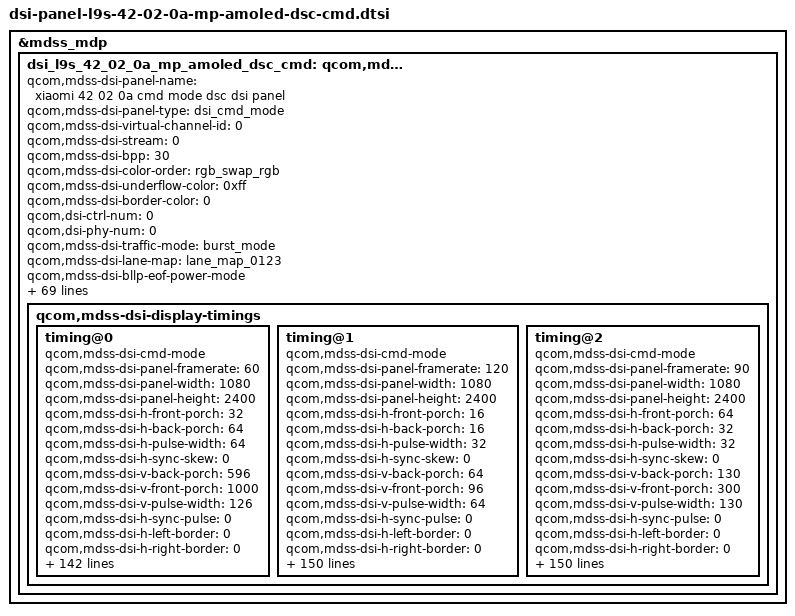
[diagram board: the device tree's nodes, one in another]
&mdss_mdp {
	dsi_l9s_42_02_0a_mp_amoled_dsc_cmd: qcom,mdss_dsi_l9s_42_02_0a_mp_amoled_dsc_cmd {
		qcom,mdss-dsi-panel-name = "xiaomi 42 02 0a cmd mode dsc dsi panel";
		qcom,mdss-dsi-panel-type = "dsi_cmd_mode";
		qcom,mdss-dsi-virtual-channel-id = <0>;
		qcom,mdss-dsi-stream = <0>;
		qcom,mdss-dsi-bpp = <30>;
		qcom,mdss-dsi-color-order = "rgb_swap_rgb";
		qcom,mdss-dsi-underflow-color = <0xff>;
		qcom,mdss-dsi-border-color = <0>;

		qcom,dsi-ctrl-num = <0>;
		qcom,dsi-phy-num = <0>;

		qcom,mdss-dsi-traffic-mode = "burst_mode";
		qcom,mdss-dsi-lane-map = "lane_map_0123";
		qcom,mdss-dsi-bllp-eof-power-mode;
		qcom,mdss-dsi-bllp-power-mode;
		qcom,mdss-dsi-lane-0-state;
		qcom,mdss-dsi-lane-1-state;
		qcom,mdss-dsi-lane-2-state;
		qcom,mdss-dsi-lane-3-state;
		qcom,mdss-dsi-dma-trigger = "trigger_sw";
		qcom,mdss-dsi-mdp-trigger = "none";
		qcom,mdss-dsi-reset-sequence =  <1 11>, <0 1>, <1 11>;
		qcom,mdss-pan-physical-width-dimension = <683>;
		qcom,mdss-pan-physical-height-dimension = <1517>;
		qcom,mdss-dsi-te-pin-select = <1>;
		qcom,mdss-dsi-wr-mem-start = <0x2c>;
		qcom,mdss-dsi-wr-mem-continue = <0x3c>;
		qcom,mdss-dsi-te-dcs-command = <1>;
		qcom,mdss-dsi-te-check-enable;
		qcom,mdss-dsi-te-using-te-pin;
		qcom,mdss-dsi-tx-eot-append;
		qcom,mdss-dsi-lp11-init;

		qcom,mdss-dsi-bl-inverted-dbv;
		qcom,bl-update-flag = "delay_until_first_frame";
		qcom,mdss-dsi-panel-mode-switch;

		qcom,mdss-dsi-panel-hdr-enabled;
		qcom,mdss-dsi-panel-hdr-color-primaries = <14500 15500 32000 17000 15500 30000 8000 3000>;
		qcom,mdss-dsi-panel-peak-brightness = <4200000>;
		qcom,mdss-dsi-panel-blackness-level = <3230>;

		qcom,mdss-dsi-display-timings {
			/* 60Hz */
			timing@0{
				qcom,mdss-dsi-cmd-mode;
				qcom,mdss-dsi-panel-framerate = <60>;
				qcom,mdss-dsi-panel-width = <1080>;
				qcom,mdss-dsi-panel-height = <2400>;
				qcom,mdss-dsi-h-front-porch = <32>;
				qcom,mdss-dsi-h-back-porch = <64>;
				qcom,mdss-dsi-h-pulse-width = <64>;
				qcom,mdss-dsi-h-sync-skew = <0>;
				qcom,mdss-dsi-v-back-porch = <596>;
				qcom,mdss-dsi-v-front-porch = <1000>;
				qcom,mdss-dsi-v-pulse-width = <126>;
				qcom,mdss-dsi-h-sync-pulse = <0>;
				qcom,mdss-dsi-h-left-border = <0>;
				qcom,mdss-dsi-h-right-border = <0>;
				qcom,mdss-dsi-v-top-border = <0>;
				qcom,mdss-dsi-v-bottom-border = <0>;
				qcom,mdss-dsi-panel-clockrate = <831000000>;
				qcom,mdss-dsi-panel-jitter = <0x5 0x1>;
				qcom,mdss-mdp-transfer-time-us = <14000>;
				qcom,mdss-dsi-on-command = [
					/* Increase VFP */
					39 00 00 00 00 00 06 F0 55 AA 52 08 00
					39 00 00 40 00 00 02 6F 08
					39 00 00 40 00 00 09 BA 01 B1 00 0A 00 16 00 00
					/* Flash load */
					39 00 00 40 00 00 06 F0 55 AA 52 08 04
					39 00 00 40 00 00 02 B1 02
					/* VBP & VFP */
					39 00 00 40 00 00 05 3B 00 14 00 0C
					/* Vesa Decode enable */
					39 00 00 40 00 00 02 90 01
					/* DSC Setting */
					39 00 00 40 00 00 13 91 AB 28 00 0C C2 00 03 1C 01 7E 00 0F 08 BB 04 3D 10 F0
					39 00 00 40 00 00 02 03 01
					39 00 00 40 00 00 02 2C 00
					/* Round Off */
					39 00 00 40 00 00 06 F0 55 AA 52 08 07
					39 00 00 40 00 00 02 C0 05
					39 00 00 40 00 00 02 C1 00
					39 00 00 40 00 00 02 C2 00
					39 00 00 40 00 00 02 C3 00
					39 00 00 40 00 00 02 C4 00
					39 00 00 40 00 00 02 C5 00
					39 00 00 40 00 00 02 C6 00
					39 00 00 40 00 00 02 C7 00
					39 00 00 40 00 00 02 C8 00
					39 00 00 40 00 00 02 CD 00
					39 00 00 40 00 00 02 CE 00
					39 00 00 40 00 00 02 CF 00
					39 00 00 40 00 00 02 D0 00
					/* Dimming OFF Setting */
					39 00 00 40 00 00 02 53 20
					/* page 0 */
					39 00 00 40 00 00 06 F0 55 AA 52 08 00
					/* Dimming 8 frame */
					39 00 00 40 00 00 02 6F 02
					39 00 00 40 00 00 03 B2 08 08
					/* TE ON Setting */
					39 00 00 40 00 00 02 35 00
					/* MIPI Speed = 831Mbps @osc 128Mhz */
					39 00 00 40 00 00 06 F0 55 AA 52 08 01
					39 00 00 40 00 00 08 C3 94 01 8C D0 22 02 00
					/* CASET/RASET Setting */
					39 00 00 40 00 00 05 2A 00 00 04 37 /* CASET 1080 */
					39 00 00 40 00 00 05 2B 00 00 09 5F /* PASET 2400 */
					/* Frame Rate 60Hz */
					39 00 00 40 00 00 02 2F 01
					/* GIR OFF */
					39 00 00 40 00 00 02 26 01
					39 00 00 40 00 00 06 F0 55 AA 52 08 00
					39 00 00 40 00 00 02 6F 05
					39 00 00 00 00 00 02 BE 88
					/* Aod no black */
					39 00 00 40 00 00 05 FF AA 55 A5 80
					39 00 00 40 00 00 02 6F 61
					39 00 00 40 00 00 02 F3 80
					39 00 00 40 00 00 06 F0 55 AA 52 08 01
					39 00 00 40 00 00 02 6F 01
					39 00 00 40 00 00 04 D2 00 00 11
					39 00 00 40 00 00 02 6F 06
					39 00 00 40 00 00 02 D2 05
					39 00 00 40 00 00 02 6F 0F
					39 00 00 40 00 00 02 D2 00
					39 00 00 40 00 00 02 6F 09
					39 00 00 00 00 00 03 D2 00 00
					/* Disable aod reload */
					39 00 00 40 00 00 06 F0 55 AA 52 08 00
					39 00 00 40 00 00 02 6F 01
					39 00 00 40 00 00 02 C0 B3
					39 00 00 40 00 00 05 FF AA 55 A5 80
					39 00 00 40 00 00 02 6F 2E
					39 00 00 40 00 00 02 FB D1
					39 00 00 40 00 00 06 F0 55 AA 52 08 04
					39 00 00 40 00 00 02 6F 0D
					39 00 00 00 00 00 02 CA 05
					/* Lhbm spot 12mm */
					39 00 00 40 00 00 06 F0 55 AA 52 08 07
					39 00 00 40 00 00 02 C0 05
					39 00 00 40 00 00 02 6F 00
					39 00 00 40 00 00 16 C9 21 00 21 C9 21 10 00 00 3F E7 B7 88 3F E7 FA 60 80 04 5D 05 90
					39 00 00 40 00 00 02 6F 15
					39 00 00 40 00 00 10 C9 81 C0 16 82 1C 73 33 A0 21 6C 0F A3 A4 00 00
					39 00 00 40 00 00 02 6F 24
					39 00 00 40 00 00 08 C9 00 00 00 00 00 00 00
					39 00 00 40 00 00 02 6F 00
					39 00 00 40 00 00 16 CA 27 00 21 C9 21 10 00 00 00 00 00 00 3F E7 FA 60 80 00 00 00 00
					39 00 00 40 00 00 02 6F 15
					39 00 00 40 00 00 10 CA 82 1D 16 82 79 73 33 A0 00 00 03 5D A4 00 00
					39 00 00 40 00 00 02 6F 24
					39 00 00 40 00 00 08 CA 00 00 00 00 00 00 00
					39 00 00 40 00 00 02 6F 00
					39 00 00 40 00 00 16 CB 2D 00 21 10 21 10 00 00 3F E8 3C 80 80 00 00 00 00 00 00 00 00
					39 00 00 40 00 00 02 6F 15
					39 00 00 40 00 00 10 CB 81 C0 74 82 1C D0 33 10 00 00 0C A4 5C 00 00
					39 00 00 40 00 00 02 6F 24
					39 00 00 40 00 00 08 CB 00 00 00 00 00 00 00
					39 00 00 40 00 00 02 6F 00
					39 00 00 40 00 00 16 CC 2B 00 21 10 21 10 00 00 00 00 00 00 80 00 00 00 7F FB BA DF 00
					39 00 00 40 00 00 02 6F 15
					39 00 00 40 00 00 10 CC 82 1D 74 82 79 D0 33 1F DE F0 00 5C 5C 00 00
					39 00 00 40 00 00 02 6F 24
					39 00 00 00 00 00 08 CC 00 00 00 00 00 00 00
					/* Sleep Out */
					39 00 00 00 50 00 02 11 00
					/* Display On */
					39 00 00 00 00 00 02 29 00];
				qcom,mdss-dsi-off-command = [
					39 00 00 00 0A 00 02 28 00
					39 00 00 00 78 00 02 10 00];
				qcom,mdss-dsi-on-command-state = "dsi_lp_mode";
				qcom,mdss-dsi-off-command-state = "dsi_lp_mode";

				qcom,mdss-dsi-timing-switch-command = [
					/* 60 Hz */
					39 00 00 00 00 00 06 F0 55 AA 52 08 02
					39 00 00 40 00 00 02 CC 00
					39 00 00 40 00 00 02 2F 01
					39 00 00 00 00 00 02 26 01
				];
				qcom,mdss-dsi-timing-switch-command-state = "dsi_hs_mode";
				qcom,mdss-dsi-timing-switch-command-update = <0x26 3 1>;

				qcom,mdss-dsi-nolp-command = [
					39 00 00 00 00 00 06 F0 55 AA 52 08 00
					39 00 00 40 00 00 02 B2 18
					39 00 00 00 32 00 02 38 00];
				qcom,mdss-dsi-nolp-command-state = "dsi_hs_mode";

				qcom,compression-mode = "dsc";
				qcom,mdss-dsc-version = <0x11>;
				qcom,mdss-dsc-scr-version = <0x0>;
				qcom,mdss-dsc-slice-height = <12>;
				qcom,mdss-dsc-slice-width = <1080>;
				qcom,mdss-dsc-slice-per-pkt = <1>;
				qcom,mdss-dsc-bit-per-component = <10>;
				qcom,mdss-dsc-bit-per-pixel = <8>;
				qcom,mdss-dsc-block-prediction-enable;
			};
			/* 120hz */
			timing@1{
				qcom,mdss-dsi-cmd-mode;
				qcom,mdss-dsi-panel-framerate = <120>;
				qcom,mdss-dsi-panel-width = <1080>;
				qcom,mdss-dsi-panel-height = <2400>;
				qcom,mdss-dsi-h-front-porch = <16>;
				qcom,mdss-dsi-h-back-porch = <16>;
				qcom,mdss-dsi-h-pulse-width = <32>;
				qcom,mdss-dsi-h-sync-skew = <0>;
				qcom,mdss-dsi-v-back-porch = <64>;
				qcom,mdss-dsi-v-front-porch = <96>;
				qcom,mdss-dsi-v-pulse-width = <64>;
				qcom,mdss-dsi-h-sync-pulse = <0>;
				qcom,mdss-dsi-h-left-border = <0>;
				qcom,mdss-dsi-h-right-border = <0>;
				qcom,mdss-dsi-v-top-border = <0>;
				qcom,mdss-dsi-v-bottom-border = <0>;
				qcom,mdss-dsi-panel-clockrate = <831000000>;
				qcom,mdss-dsi-panel-jitter = <0x5 0x1>;
				qcom,mdss-mdp-transfer-time-us = <8000>;
				qcom,mdss-dsi-on-command = [
					/* Increase VFP */
					39 00 00 00 00 00 06 F0 55 AA 52 08 00
					39 00 00 40 00 00 02 6F 08
					39 00 00 40 00 00 09 BA 01 B1 00 0A 00 16 00 00
					/* Flash load */
					39 00 00 40 00 00 06 F0 55 AA 52 08 04
					39 00 00 40 00 00 02 B1 02
					/* VBP & VFP */
					39 00 00 40 00 00 05 3B 00 14 00 0C
					/* Vesa Decode enable */
					39 00 00 40 00 00 02 90 01
					/* DSC Setting */
					39 00 00 40 00 00 13 91 AB 28 00 0C C2 00 03 1C 01 7E 00 0F 08 BB 04 3D 10 F0
					39 00 00 40 00 00 02 03 01
					39 00 00 40 00 00 02 2C 00
					/* Round Off */
					39 00 00 40 00 00 06 F0 55 AA 52 08 07
					39 00 00 40 00 00 02 C0 05
					39 00 00 40 00 00 02 C1 00
					39 00 00 40 00 00 02 C2 00
					39 00 00 40 00 00 02 C3 00
					39 00 00 40 00 00 02 C4 00
					39 00 00 40 00 00 02 C5 00
					39 00 00 40 00 00 02 C6 00
					39 00 00 40 00 00 02 C7 00
					39 00 00 40 00 00 02 C8 00
					39 00 00 40 00 00 02 CD 00
					39 00 00 40 00 00 02 CE 00
					39 00 00 40 00 00 02 CF 00
					39 00 00 40 00 00 02 D0 00
					/* Dimming OFF Setting */
					39 00 00 40 00 00 02 53 20
					/* page 0 */
					39 00 00 40 00 00 06 F0 55 AA 52 08 00
					/* Dimming 8 frame */
					39 00 00 40 00 00 02 6F 02
					39 00 00 40 00 00 03 B2 08 08
					/* TE ON Setting */
					39 00 00 40 00 00 02 35 00
					/* MIPI Speed = 831Mbps @osc 128Mhz */
					39 00 00 40 00 00 06 F0 55 AA 52 08 01
					39 00 00 40 00 00 08 C3 94 01 8C D0 22 02 00
					/* CASET/RASET Setting */
					39 00 00 40 00 00 05 2A 00 00 04 37 /* CASET 1080 */
					39 00 00 40 00 00 05 2B 00 00 09 5F /* PASET 2400 */
					/* Frame Rate 120Hz */
					39 00 00 40 00 00 02 2F 02
					/* GIR OFF */
					39 00 00 40 00 00 06 F0 55 AA 52 08 00
					39 00 00 40 00 00 02 6F 09
					39 00 00 40 00 00 02 C0 20
					39 00 00 40 00 00 06 F0 55 AA 52 08 02
					39 00 00 40 00 00 02 CC 30
					39 00 00 40 14 00 02 CE 01
					39 00 00 40 00 00 02 CC 00
					39 00 00 40 00 00 06 F0 55 AA 52 08 00
					39 00 00 40 00 00 02 6F 05
					39 00 00 00 00 00 02 BE 88
					/* Aod no black */
					39 00 00 40 00 00 05 FF AA 55 A5 80
					39 00 00 40 00 00 02 6F 61
					39 00 00 40 00 00 02 F3 80
					39 00 00 40 00 00 06 F0 55 AA 52 08 01
					39 00 00 40 00 00 02 6F 01
					39 00 00 40 00 00 04 D2 00 00 11
					39 00 00 40 00 00 02 6F 06
					39 00 00 40 00 00 02 D2 05
					39 00 00 40 00 00 02 6F 0F
					39 00 00 40 00 00 02 D2 00
					39 00 00 40 00 00 02 6F 09
					39 00 00 00 00 00 03 D2 00 00
					/* Disable aod reload */
					39 00 00 40 00 00 06 F0 55 AA 52 08 00
					39 00 00 40 00 00 02 6F 01
					39 00 00 40 00 00 02 C0 B3
					39 00 00 40 00 00 05 FF AA 55 A5 80
					39 00 00 40 00 00 02 6F 2E
					39 00 00 40 00 00 02 FB D1
					39 00 00 40 00 00 06 F0 55 AA 52 08 04
					39 00 00 40 00 00 02 6F 0D
					39 00 00 00 00 00 02 CA 05
					/* Lhbm spot 12mm */
					39 00 00 40 00 00 06 F0 55 AA 52 08 07
					39 00 00 40 00 00 02 C0 05
					39 00 00 40 00 00 02 6F 00
					39 00 00 40 00 00 16 C9 21 00 21 C9 21 10 00 00 3F E7 B7 88 3F E7 FA 60 80 04 5D 05 90
					39 00 00 40 00 00 02 6F 15
					39 00 00 40 00 00 10 C9 81 C0 16 82 1C 73 33 A0 21 6C 0F A3 A4 00 00
					39 00 00 40 00 00 02 6F 24
					39 00 00 40 00 00 08 C9 00 00 00 00 00 00 00
					39 00 00 40 00 00 02 6F 00
					39 00 00 40 00 00 16 CA 27 00 21 C9 21 10 00 00 00 00 00 00 3F E7 FA 60 80 00 00 00 00
					39 00 00 40 00 00 02 6F 15
					39 00 00 40 00 00 10 CA 82 1D 16 82 79 73 33 A0 00 00 03 5D A4 00 00
					39 00 00 40 00 00 02 6F 24
					39 00 00 40 00 00 08 CA 00 00 00 00 00 00 00
					39 00 00 40 00 00 02 6F 00
					39 00 00 40 00 00 16 CB 2D 00 21 10 21 10 00 00 3F E8 3C 80 80 00 00 00 00 00 00 00 00
					39 00 00 40 00 00 02 6F 15
					39 00 00 40 00 00 10 CB 81 C0 74 82 1C D0 33 10 00 00 0C A4 5C 00 00
					39 00 00 40 00 00 02 6F 24
					39 00 00 40 00 00 08 CB 00 00 00 00 00 00 00
					39 00 00 40 00 00 02 6F 00
					39 00 00 40 00 00 16 CC 2B 00 21 10 21 10 00 00 00 00 00 00 80 00 00 00 7F FB BA DF 00
					39 00 00 40 00 00 02 6F 15
					39 00 00 40 00 00 10 CC 82 1D 74 82 79 D0 33 1F DE F0 00 5C 5C 00 00
					39 00 00 40 00 00 02 6F 24
					39 00 00 00 00 00 08 CC 00 00 00 00 00 00 00
					/* Sleep Out */
					39 00 00 00 50 00 02 11 00
					/* Display On */
					39 00 00 00 00 00 02 29 00];
				qcom,mdss-dsi-off-command = [
					39 00 00 00 14 00 02 28 00
					39 00 00 00 78 00 02 10 00];
				qcom,mdss-dsi-on-command-state = "dsi_lp_mode";
				qcom,mdss-dsi-off-command-state = "dsi_lp_mode";

				qcom,mdss-dsi-timing-switch-command = [
					/* 120 Hz   cmd_1*/
					39 00 00 00 00 00 02 2F 02
					39 00 00 40 00 00 06 F0 55 AA 52 08 00
					39 00 00 40 00 00 02 6F 09
					39 00 00 40 00 00 02 C0 20
					39 00 00 40 00 00 06 F0 55 AA 52 08 02
					39 00 00 40 00 00 02 CC 30
					39 00 00 00 14 00 02 CE 01
					/*120 Hz  cmd_2*/
					39 00 00 00 00 00 06 F0 55 AA 52 08 02
					39 00 00 00 00 00 02 CC 00
				];
				qcom,mdss-dsi-timing-switch-command-update = <0xC0 3 1>;
				qcom,mdss-dsi-timing-switch-command-state = "dsi_hs_mode";

				qcom,mdss-dsi-nolp-command = [
					39 00 00 00 00 00 06 F0 55 AA 52 08 00
					39 00 00 40 00 00 02 B2 18
					39 00 00 00 00 00 02 38 00
					39 00 00 00 00 00 02 2F 02];
				qcom,mdss-dsi-nolp-command-state = "dsi_hs_mode";

				qcom,compression-mode = "dsc";
				qcom,mdss-dsc-version = <0x11>;
				qcom,mdss-dsc-scr-version = <0x0>;
				qcom,mdss-dsc-slice-height = <12>;
				qcom,mdss-dsc-slice-width = <1080>;
				qcom,mdss-dsc-slice-per-pkt = <1>;
				qcom,mdss-dsc-bit-per-component = <10>;
				qcom,mdss-dsc-bit-per-pixel = <8>;
				qcom,mdss-dsc-block-prediction-enable;
			};
			/* 90hz */
			timing@2{
				qcom,mdss-dsi-cmd-mode;
				qcom,mdss-dsi-panel-framerate = <90>;
				qcom,mdss-dsi-panel-width = <1080>;
				qcom,mdss-dsi-panel-height = <2400>;
				qcom,mdss-dsi-h-front-porch = <64>;
				qcom,mdss-dsi-h-back-porch = <32>;
				qcom,mdss-dsi-h-pulse-width = <32>;
				qcom,mdss-dsi-h-sync-skew = <0>;
				qcom,mdss-dsi-v-back-porch = <130>;
				qcom,mdss-dsi-v-front-porch = <300>;
				qcom,mdss-dsi-v-pulse-width = <130>;
				qcom,mdss-dsi-h-sync-pulse = <0>;
				qcom,mdss-dsi-h-left-border = <0>;
				qcom,mdss-dsi-h-right-border = <0>;
				qcom,mdss-dsi-v-top-border = <0>;
				qcom,mdss-dsi-v-bottom-border = <0>;
				qcom,mdss-dsi-panel-clockrate = <831000000>;
				qcom,mdss-dsi-panel-jitter = <0x5 0x1>;
				qcom,mdss-mdp-transfer-time-us = <10000>;
				qcom,mdss-dsi-on-command = [
					/* Increase VFP */
					39 00 00 40 00 00 06 F0 55 AA 52 08 00
					39 00 00 40 00 00 02 6F 08
					39 00 00 40 00 00 09 BA 01 B1 00 0A 00 16 00 00
					/* Flash load */
					39 00 00 40 00 00 06 F0 55 AA 52 08 04
					39 00 00 40 00 00 02 B1 02
					/* VBP & VFP */
					39 00 00 40 00 00 05 3B 00 14 00 0C
					/* Vesa Decode enable */
					39 00 00 40 00 00 02 90 01
					/* DSC Setting */
					39 00 00 40 00 00 13 91 AB 28 00 0C C2 00 03 1C 01 7E 00 0F 08 BB 04 3D 10 F0
					39 00 00 40 00 00 02 03 01
					39 00 00 40 00 00 02 2C 00
					/* Round Off */
					39 00 00 40 00 00 06 F0 55 AA 52 08 07
					39 00 00 40 00 00 02 C0 05
					39 00 00 40 00 00 02 C1 00
					39 00 00 40 00 00 02 C2 00
					39 00 00 40 00 00 02 C3 00
					39 00 00 40 00 00 02 C4 00
					39 00 00 40 00 00 02 C5 00
					39 00 00 40 00 00 02 C6 00
					39 00 00 40 00 00 02 C7 00
					39 00 00 40 00 00 02 C8 00
					39 00 00 40 00 00 02 CD 00
					39 00 00 40 00 00 02 CE 00
					39 00 00 40 00 00 02 CF 00
					39 00 00 40 00 00 02 D0 00
					/* Dimming OFF Setting */
					39 00 00 40 00 00 02 53 20
					/* page 0 */
					39 00 00 40 00 00 06 F0 55 AA 52 08 00
					/* Dimming 8 frame */
					39 00 00 40 00 00 02 6F 02
					39 00 00 40 00 00 03 B2 08 08
					/* TE ON Setting */
					39 00 00 40 00 00 02 35 00
					/* MIPI Speed = 831Mbps @osc 128Mhz */
					39 00 00 40 00 00 06 F0 55 AA 52 08 01
					39 00 00 40 00 00 08 C3 94 01 8C D0 22 02 00
					/* CASET/RASET Setting */
					39 00 00 40 00 00 05 2A 00 00 04 37 /* CASET 1080 */
					39 00 00 40 00 00 05 2B 00 00 09 5F /* PASET 2400 */
					/* Frame Rate 90Hz */
					39 00 00 40 00 00 02 2F 03
					/* GIR OFF */
					39 00 00 40 00 00 06 F0 55 AA 52 08 00
					39 00 00 40 00 00 02 6F 0A
					39 00 00 40 00 00 02 C0 20
					39 00 00 40 00 00 06 F0 55 AA 52 08 02
					39 00 00 40 00 00 02 CC 30
					39 00 00 40 14 00 02 CE 01
					39 00 00 40 00 00 02 CC 00
					39 00 00 40 00 00 06 F0 55 AA 52 08 00
					39 00 00 40 00 00 02 6F 05
					39 00 00 00 00 00 02 BE 88
					/* Aod no black */
					39 00 00 40 00 00 05 FF AA 55 A5 80
					39 00 00 40 00 00 02 6F 61
					39 00 00 40 00 00 02 F3 80
					39 00 00 40 00 00 06 F0 55 AA 52 08 01
					39 00 00 40 00 00 02 6F 01
					39 00 00 40 00 00 04 D2 00 00 11
					39 00 00 40 00 00 02 6F 06
					39 00 00 40 00 00 02 D2 05
					39 00 00 40 00 00 02 6F 0F
					39 00 00 40 00 00 02 D2 00
					39 00 00 40 00 00 02 6F 09
					39 00 00 00 00 00 03 D2 00 00
					/* Disable aod reload */
					39 00 00 40 00 00 06 F0 55 AA 52 08 00
					39 00 00 40 00 00 02 6F 01
					39 00 00 40 00 00 02 C0 B3
					39 00 00 40 00 00 05 FF AA 55 A5 80
					39 00 00 40 00 00 02 6F 2E
					39 00 00 40 00 00 02 FB D1
					39 00 00 40 00 00 06 F0 55 AA 52 08 04
					39 00 00 40 00 00 02 6F 0D
					39 00 00 00 00 00 02 CA 05
					/* Lhbm spot 12mm */
					39 00 00 40 00 00 06 F0 55 AA 52 08 07
					39 00 00 40 00 00 02 C0 05
					39 00 00 40 00 00 02 6F 00
					39 00 00 40 00 00 16 C9 21 00 21 C9 21 10 00 00 3F E7 B7 88 3F E7 FA 60 80 04 5D 05 90
					39 00 00 40 00 00 02 6F 15
					39 00 00 40 00 00 10 C9 81 C0 16 82 1C 73 33 A0 21 6C 0F A3 A4 00 00
					39 00 00 40 00 00 02 6F 24
					39 00 00 40 00 00 08 C9 00 00 00 00 00 00 00
					39 00 00 40 00 00 02 6F 00
					39 00 00 40 00 00 16 CA 27 00 21 C9 21 10 00 00 00 00 00 00 3F E7 FA 60 80 00 00 00 00
					39 00 00 40 00 00 02 6F 15
					39 00 00 40 00 00 10 CA 82 1D 16 82 79 73 33 A0 00 00 03 5D A4 00 00
					39 00 00 40 00 00 02 6F 24
					39 00 00 40 00 00 08 CA 00 00 00 00 00 00 00
					39 00 00 40 00 00 02 6F 00
					39 00 00 40 00 00 16 CB 2D 00 21 10 21 10 00 00 3F E8 3C 80 80 00 00 00 00 00 00 00 00
					39 00 00 40 00 00 02 6F 15
					39 00 00 40 00 00 10 CB 81 C0 74 82 1C D0 33 10 00 00 0C A4 5C 00 00
					39 00 00 40 00 00 02 6F 24
					39 00 00 40 00 00 08 CB 00 00 00 00 00 00 00
					39 00 00 40 00 00 02 6F 00
					39 00 00 40 00 00 16 CC 2B 00 21 10 21 10 00 00 00 00 00 00 80 00 00 00 7F FB BA DF 00
					39 00 00 40 00 00 02 6F 15
					39 00 00 40 00 00 10 CC 82 1D 74 82 79 D0 33 1F DE F0 00 5C 5C 00 00
					39 00 00 40 00 00 02 6F 24
					39 00 00 00 00 00 08 CC 00 00 00 00 00 00 00
					/* Sleep Out */
					39 00 00 00 50 00 02 11 00
					/* Display On */
					39 00 00 00 00 00 02 29 00];
				qcom,mdss-dsi-off-command = [
					39 00 00 00 14 00 02 28 00
					39 00 00 00 78 00 02 10 00];
				qcom,mdss-dsi-on-command-state = "dsi_lp_mode";
				qcom,mdss-dsi-off-command-state = "dsi_lp_mode";

				qcom,mdss-dsi-timing-switch-command = [
					/* 90 Hz  cmd_1*/
					39 00 00 00 00 00 02 2F 03
					39 00 00 40 00 00 06 F0 55 AA 52 08 00
					39 00 00 40 00 00 02 6F 0A
					39 00 00 40 00 00 02 C0 20
					39 00 00 40 00 00 06 F0 55 AA 52 08 02
					39 00 00 40 00 00 02 CC 30
					39 00 00 00 14 00 02 CE 01
					/* 90 Hz  */
					39 00 00 00 00 00 06 F0 55 AA 52 08 02
					39 00 00 00 00 00 02 CC 00
				];
				qcom,mdss-dsi-timing-switch-command-update = <0xC0 3 1>;
				qcom,mdss-dsi-timing-switch-command-state = "dsi_hs_mode";

				qcom,mdss-dsi-nolp-command = [
					39 00 00 00 00 00 06 F0 55 AA 52 08 00
					39 00 00 40 00 00 02 B2 18
					39 00 00 00 00 00 02 38 00
					39 00 00 00 00 00 02 2F 03];
				qcom,mdss-dsi-nolp-command-state = "dsi_hs_mode";

				qcom,compression-mode = "dsc";
				qcom,mdss-dsc-version = <0x11>;
				qcom,mdss-dsc-scr-version = <0x0>;
				qcom,mdss-dsc-slice-height = <12>;
				qcom,mdss-dsc-slice-width = <1080>;
				qcom,mdss-dsc-slice-per-pkt = <1>;
				qcom,mdss-dsc-bit-per-component = <10>;
				qcom,mdss-dsc-bit-per-pixel = <8>;
				qcom,mdss-dsc-block-prediction-enable;
			};
		};
	};
};

&dsi_l9s_42_02_0a_mp_amoled_dsc_cmd {
	mi,panel-id = <0x004C3953 0x00420200>;
	mi,hbm-51-ctl-flag;
	mi,bl-51ctl-32bit-flag;
	mi,aod-bl-51ctl-flag;
	mi,aod-brightness = <0x155 0x0FFE>;
	mi,hbm-off-51-index = <0>;
	mi,hbm-fod-off-51-index = <0>;
	mi,hbm-bl-min-level = <1>;
	mi,hbm-bl-max-level = <2047>;
	mi,max-brightness-clone = <4095>;
	mi,mdss-dsi-fac-bl-max-level = <2047>;
	mi,mdss-fac-brightness-max-level = <2047>;
	mi,thermal-dimming-flag;
	mi,mdss-dsi-panel-dc-type = <0>;

	mi,local-hbm-enabled;
	mi,doze-hbm-dbv-level = <245>;
	mi,doze-lbm-dbv-level = <20>;
	mi,fod-low-brightness-clone-threshold = <38>;
	mi,fod-low-brightness-lux-threshold = <1>;
	mi,local-hbm-white-1000nit-update-flag;
	mi,local-hbm-white-110nit-update-flag;
	mi,local-hbm-green-500nit-update-flag;
	mi,local-hbm-alpha-ctrl-aa-area;
	mi,need-fod-animal-in-normal-enabled;

	mi,flat-update-flag;
	mi,flat-need-sync-te;

	/* IRQF_ONESHOT | IRQF_TRIGGER_LOW */
	mi,esd-err-irq-gpio = <&tlmm 11 0x2008>;

	mi,panel-aod-to-off-command-need-enabled;

	mi,panel-on-dimming-delay = <120>;

	qcom,esd-check-enabled;
	qcom,esd-aod-check-enabled;
	qcom,mdss-dsi-panel-status-check-mode = "reg_read";
	qcom,mdss-dsi-panel-status-offset-command = [
		39 01 00 00 00 00 05 FF AA 55 A5 81
		15 01 00 00 00 00 02 6F 0F];
	qcom,mdss-dsi-panel-status-command = [06 01 00 00 00 00 01 FA];
	qcom,mdss-dsi-panel-status-command-state = "dsi_lp_mode";
	qcom,mdss-dsi-panel-status-offset-command-state = "dsi_lp_mode";
	qcom,mdss-dsi-panel-status-value = <0x00>;
	qcom,mdss-dsi-panel-status-read-length = <1>;

	qcom,mdss-dsi-display-timings {
		/* 60Hz */
		timing@0{
			mi,mdss-dsc-panel-id = <0x004C3953 0x00420200>;
			/*<flat on gamma, flat off gamma>*/
			mi,mdss-flat-status-control-gamma-cfg = <0x04 0x01>;
			mi,mdss-dsi-dimmingon-command = [39 00 00 00 00 00 02 53 28];
			mi,mdss-dsi-dimmingon-command-state = "dsi_hs_mode";
			mi,mdss-dsi-dimmingoff-command = [39 00 00 00 00 00 02 53 20];
			mi,mdss-dsi-dimmingoff-command-state = "dsi_hs_mode";

			mi,mdss-dsi-hbm-on-command = [39 00 00 00 00 00 05 51 0F FF 00 00];
			mi,mdss-dsi-hbm-on-command-state = "dsi_lp_mode";
			mi,mdss-dsi-hbm-off-command = [39 00 00 00 00 00 05 51 07 FF 00 00];
			mi,mdss-dsi-hbm-off-command-state = "dsi_lp_mode";
			mi,mdss-dsi-switch-page-command = [
			/* switch page, last byte is page config */
				39 00 00 00 00 00 06 F0 55 AA 52 08 00
			];
			/* <mipi_address  update_index  update_length> */
			mi,mdss-dsi-switch-page-command-update = <0xF0 0 5>;
			mi,mdss-dsi-switch-page-command-state = "dsi_lp_mode";

			mi,mdss-dsi-flat-mode-read-pre-command = [
				39 00 00 00 00 00 06 F0 55 AA 52 08 00
				39 00 00 00 00 00 02 6F 3F
			];
			mi,mdss-dsi-flat-mode-read-pre-command-state = "dsi_lp_mode";

			mi,mdss-dsi-flat-mode-off-read-pre-command = [
				39 00 00 00 00 00 06 F0 55 AA 52 08 00
				39 00 00 00 00 00 02 6F 48
			];
			mi,mdss-dsi-flat-mode-off-read-pre-command-state = "dsi_lp_mode";

			mi,mdss-dsi-flat-mode-on-command = [
				/* 60 Hz */
				39 00 00 00 00 00 02 2F 01
				39 00 00 40 00 00 02 26 04
				39 00 00 40 00 00 06 F0 55 AA 52 08 08
				39 00 00 40 00 00 02 6F 07
				39 00 00 20 00 00 05 B9 00 00 00 00
			];
			/* <mipi_address  update_index  update_length> */
			mi,mdss-dsi-flat-mode-on-command-update = <0xB9 4 4>;
			mi,mdss-dsi-flat-mode-on-command-state = "dsi_lp_mode";

			mi,mdss-dsi-flat-mode-off-command = [
				/* 60 Hz */
				39 00 00 00 00 00 02 2F 01
				39 00 00 40 00 00 02 26 01
				39 00 00 40 00 00 06 F0 55 AA 52 08 08
				39 00 00 40 00 00 02 6F 07
				39 00 00 20 00 00 05 B9 00 00 00 18
			];
			/* <mipi_address  update_index  update_length> */
			mi,mdss-dsi-flat-mode-off-command-update = <0xB9 4 4>;
			mi,mdss-dsi-flat-mode-off-command-state = "dsi_lp_mode";

			mi,mdss-dsi-doze-hbm-command = [
				39 00 00 00 00 00 02 2F 01
				39 00 00 40 00 00 02 26 01
				39 00 00 40 00 00 06 F0 55 AA 52 08 00
				39 00 00 40 00 00 02 B2 08
				39 00 00 40 00 00 05 51 00 F5 0F FE
				39 00 00 00 00 00 02 39 00
			];
			mi,mdss-dsi-doze-hbm-command-state = "dsi_lp_mode";

			mi,mdss-dsi-doze-lbm-command = [
				39 00 00 00 00 00 02 2F 01
				39 00 00 40 00 00 02 26 01
				39 00 00 40 00 00 06 F0 55 AA 52 08 00
				39 00 00 40 00 00 02 B2 08
				39 00 00 40 00 00 05 51 00 14 01 55
				39 00 00 00 00 00 02 39 00
			];
			mi,mdss-dsi-doze-lbm-command-state = "dsi_lp_mode";

			mi,mdss-dsi-doze-hbm-nolp-command = [
				39 00 00 00 00 00 06 F0 55 AA 52 08 00
				39 00 00 40 00 00 02 B2 18
				39 00 00 40 00 00 05 51 00 F5 0F FE
				39 00 00 00 00 00 02 38 00
			];
			mi,mdss-dsi-doze-hbm-nolp-command-state = "dsi_lp_mode";

			mi,mdss-dsi-doze-lbm-nolp-command = [
				39 00 00 00 00 00 06 F0 55 AA 52 08 00
				39 00 00 40 00 00 02 B2 18
				39 00 00 40 00 00 05 51 00 14 01 55
				39 00 00 00 00 00 02 38 00
			];
			mi,mdss-dsi-doze-lbm-nolp-command-state = "dsi_lp_mode";

			mi,mdss-dsi-local-hbm-normal-white-1000nit-command = [
				39 00 00 00 00 00 06 F0 55 AA 52 08 00
				39 00 00 40 00 00 02 6F 29
				39 00 00 40 00 00 02 D9 00
				39 00 00 40 00 00 02 6F 01
				39 00 00 40 00 00 02 D9 80
				39 00 00 40 00 00 02 6F 07
				39 00 00 40 00 00 03 B2 07 FF
				39 00 00 40 00 00 02 6F 17
				39 00 00 40 00 00 03 B2 07 FF
				39 00 00 40 00 00 02 6F 1F
				39 00 00 40 00 00 03 B2 00 50
				39 00 00 40 00 00 06 F0 55 AA 52 08 02
				39 00 00 40 00 00 02 6F 08
				39 00 00 40 00 00 07 D0 0B 07 09 7B 0C 1D
				39 00 00 40 00 00 06 F0 55 AA 52 08 07
				39 00 00 40 00 00 02 C0 05
				39 00 00 40 00 00 02 53 20
				39 00 00 40 00 00 05 88 02 1C 08 73
				39 00 00 40 00 00 03 51 07 FF
				39 00 00 40 00 00 03 87 04 4E
				39 00 00 40 00 00 02 6F 02
				39 00 00 00 30 00 02 87 05
			];
			mi,mdss-dsi-local-hbm-normal-white-1000nit-command-update = <0x87 19 2>, <0xD0 13 6>;
			mi,mdss-dsi-local-hbm-normal-white-1000nit-command-state = "dsi_hs_mode";

			mi,mdss-dsi-local-hbm-hlpm-white-1000nit-command = [
				/* AOD off */
				39 00 00 00 00 00 06 F0 55 AA 52 08 00
				39 00 00 40 00 00 02 B2 18
				39 00 00 40 00 00 02 38 00
				/* Local HBM setting*/
				39 00 00 40 00 00 06 F0 55 AA 52 08 00
				39 00 00 40 00 00 02 6F 29
				39 00 00 40 00 00 02 D9 00
				39 00 00 40 00 00 02 6F 01
				39 00 00 40 00 00 02 D9 80
				39 00 00 40 00 00 02 6F 07
				39 00 00 40 00 00 03 B2 07 FF
				39 00 00 40 00 00 02 6F 17
				39 00 00 40 00 00 03 B2 07 FF
				39 00 00 40 00 00 02 6F 1F
				39 00 00 40 00 00 03 B2 00 50
				39 00 00 40 00 00 06 F0 55 AA 52 08 02
				39 00 00 40 00 00 02 6F 08
				39 00 00 40 00 00 07 D0 0B 07 09 7B 0C 1D
				39 00 00 40 00 00 06 F0 55 AA 52 08 07
				39 00 00 40 00 00 02 C0 05
				39 00 00 40 00 00 02 53 20
				39 00 00 40 00 00 05 88 02 1C 08 73
				39 00 00 40 00 00 03 51 07 FF
				39 00 00 40 00 00 03 87 04 4E
				39 00 00 40 00 00 02 6F 02
				39 00 00 00 30 00 02 87 05
			];
			mi,mdss-dsi-local-hbm-hlpm-white-1000nit-command-update = <0x87 22 2>, <0xD0 16 6>;
			mi,mdss-dsi-local-hbm-hlpm-white-1000nit-command-state = "dsi_hs_mode";

			mi,mdss-dsi-local-hbm-normal-white-110nit-command = [
				39 00 00 00 00 00 06 F0 55 AA 52 08 00
				39 00 00 40 00 00 02 6F 29
				39 00 00 40 00 00 02 D9 00
				39 00 00 40 00 00 02 6F 01
				39 00 00 40 00 00 02 D9 80
				39 00 00 40 00 00 02 6F 07
				39 00 00 40 00 00 03 B2 07 FF
				39 00 00 40 00 00 02 6F 17
				39 00 00 40 00 00 03 B2 07 FF
				39 00 00 40 00 00 02 6F 1F
				39 00 00 40 00 00 03 B2 00 50
				39 00 00 40 00 00 06 F0 55 AA 52 08 02
				39 00 00 40 00 00 02 6F 08
				39 00 00 40 00 00 07 D0 0B 07 09 7B 0C 1D
				39 00 00 40 00 00 06 F0 55 AA 52 08 07
				39 00 00 40 00 00 02 C0 05
				39 00 00 40 00 00 02 53 20
				39 00 00 40 00 00 05 88 02 1C 08 73
				39 00 00 40 00 00 03 51 07 FF
				39 00 00 40 00 00 03 87 04 4E
				39 00 00 40 00 00 02 6F 02
				39 00 00 00 30 00 02 87 05
			];
			mi,mdss-dsi-local-hbm-normal-white-110nit-command-update = <0x87 19 2>, <0xD0 13 6>;
			mi,mdss-dsi-local-hbm-normal-white-110nit-command-state = "dsi_hs_mode";

			mi,mdss-dsi-local-hbm-hlpm-white-110nit-command = [
				/* AOD off */
				39 00 00 00 00 00 06 F0 55 AA 52 08 00
				39 00 00 40 00 00 02 B2 18
				39 00 00 40 00 00 02 38 00
				/* Local HBM setting*/
				39 00 00 40 00 00 06 F0 55 AA 52 08 00
				39 00 00 40 00 00 02 6F 29
				39 00 00 40 00 00 02 D9 00
				39 00 00 40 00 00 02 6F 01
				39 00 00 40 00 00 02 D9 80
				39 00 00 40 00 00 02 6F 07
				39 00 00 40 00 00 03 B2 07 FF
				39 00 00 40 00 00 02 6F 17
				39 00 00 40 00 00 03 B2 07 FF
				39 00 00 40 00 00 02 6F 1F
				39 00 00 40 00 00 03 B2 00 50
				39 00 00 40 00 00 06 F0 55 AA 52 08 02
				39 00 00 40 00 00 02 6F 08
				39 00 00 40 00 00 07 D0 0B 07 09 7B 0C 1D
				39 00 00 40 00 00 06 F0 55 AA 52 08 07
				39 00 00 40 00 00 02 C0 05
				39 00 00 40 00 00 02 53 20
				39 00 00 40 00 00 05 88 02 1C 08 73
				39 00 00 40 00 00 03 51 07 FF
				39 00 00 40 00 00 03 87 04 4E
				39 00 00 40 00 00 02 6F 02
				39 00 00 00 30 00 02 87 05
			];
			mi,mdss-dsi-local-hbm-hlpm-white-110nit-command-update = <0x87 22 2>, <0xD0 16 6>;
			mi,mdss-dsi-local-hbm-hlpm-white-110nit-command-state = "dsi_hs_mode";

			mi,mdss-dsi-local-hbm-normal-green-500nit-command = [
				39 00 00 00 00 00 06 F0 55 AA 52 08 00
				39 00 00 40 00 00 02 6F 29
				39 00 00 40 00 00 02 D9 00
				39 00 00 40 00 00 02 6F 01
				39 00 00 40 00 00 02 D9 80
				39 00 00 40 00 00 02 6F 07
				39 00 00 40 00 00 03 B2 07 FF
				39 00 00 40 00 00 02 6F 17
				39 00 00 40 00 00 03 B2 07 FF
				39 00 00 40 00 00 02 6F 1F
				39 00 00 40 00 00 03 B2 00 50
				39 00 00 40 00 00 06 F0 55 AA 52 08 02
				39 00 00 40 00 00 02 6F 08
				39 00 00 40 00 00 07 D0 00 00 09 40 00 00
				39 00 00 40 00 00 06 F0 55 AA 52 08 07
				39 00 00 40 00 00 02 C0 05
				39 00 00 40 00 00 02 53 20
				39 00 00 40 00 00 05 88 02 1C 08 73
				39 00 00 40 00 00 03 51 07 FF
				39 00 00 40 00 00 03 87 04 4E
				39 00 00 40 00 00 02 6F 02
				39 00 00 00 30 00 02 87 05
			];
			mi,mdss-dsi-local-hbm-normal-green-500nit-command-update = <0x87 19 2>, <0xD0 13 6>;
			mi,mdss-dsi-local-hbm-normal-green-500nit-command-state = "dsi_hs_mode";

			mi,mdss-dsi-local-hbm-off-to-normal-command = [
				39 00 00 00 00 00 02 53 20
				39 00 00 40 00 00 03 51 00 00
				39 00 00 40 00 00 02 6F 02
				39 00 00 00 00 00 02 87 04
			];
			mi,mdss-dsi-local-hbm-off-to-normal-command-update = <0x51 1 2>;
			mi,mdss-dsi-local-hbm-off-to-normal-command-state = "dsi_hs_mode";

			mi,mdss-dsi-local-hbm-off-to-hbm-command = [
				39 00 00 00 00 00 02 53 20
				39 00 00 40 00 00 03 51 00 00
				39 00 00 40 00 00 02 6F 02
				39 00 00 00 00 00 02 87 04
			];
			mi,mdss-dsi-local-hbm-off-to-hbm-command-update = <0x51 1 2>;
			mi,mdss-dsi-local-hbm-off-to-hbm-command-state = "dsi_hs_mode";

			mi,mdss-dsi-local-hbm-off-to-hlpm-command = [
				/* local hbm off */
				39 00 00 00 00 00 02 53 20
				39 00 00 40 00 00 03 51 00 00
				39 00 00 40 00 00 02 6F 02
				39 00 00 40 00 00 02 87 04
				/* aod hbm */
				39 00 00 40 00 00 02 2F 01
				39 00 00 40 00 00 02 26 01
				39 00 00 40 00 00 06 F0 55 AA 52 08 00
				39 00 00 40 00 00 02 B2 08
				39 00 00 40 00 00 05 51 00 F5 0F FF
				39 00 00 00 00 00 02 39 00
			];
			mi,mdss-dsi-local-hbm-off-to-hlpm-command-state = "dsi_hs_mode";

			mi,mdss-dsi-local-hbm-off-to-llpm-command = [
				/* local hbm off */
				39 00 00 00 00 00 02 53 20
				39 00 00 40 00 00 03 51 00 00
				39 00 00 40 00 00 02 6F 02
				39 00 00 40 00 00 02 87 04
				/* aod lbm */
				39 00 00 40 00 00 02 2F 01
				39 00 00 40 00 00 02 26 01
				39 00 00 40 00 00 06 F0 55 AA 52 08 00
				39 00 00 40 00 00 02 B2 08
				39 00 00 40 00 00 05 51 00 14 01 55
				39 00 00 00 00 00 02 39 00
			];
			mi,mdss-dsi-local-hbm-off-to-llpm-command-state = "dsi_hs_mode";

			mi,mdss-dsi-pre-doze-to-off-command = [
				39 01 00 00 00 00 06 F0 55 AA 52 08 01
				39 01 00 00 00 00 02 CE 0C];
			mi,mdss-dsi-pre-doze-to-off-command-state = "dsi_hs_mode";
		};

		/* 120Hz */
		timing@1{
			mi,mdss-dsc-panel-id = <0x004C3953 0x00420200>;
			/*<flat on gamma, flat off gamma>*/
			mi,mdss-flat-status-control-gamma-cfg = <0x60 0x20>;
			mi,mdss-dsi-dimmingon-command = [39 00 00 00 00 00 02 53 28];
			mi,mdss-dsi-dimmingon-command-state = "dsi_hs_mode";
			mi,mdss-dsi-dimmingoff-command = [39 00 00 00 00 00 02 53 20];
			mi,mdss-dsi-dimmingoff-command-state = "dsi_hs_mode";

			mi,mdss-dsi-hbm-on-command = [39 00 00 00 00 00 05 51 0F FF 00 00];
			mi,mdss-dsi-hbm-on-command-state = "dsi_lp_mode";
			mi,mdss-dsi-hbm-off-command = [39 00 00 00 00 00 05 51 07 FF 00 00];
			mi,mdss-dsi-hbm-off-command-state = "dsi_lp_mode";

			mi,mdss-dsi-switch-page-command = [
			/* switch page, last byte is page config */
				39 00 00 00 00 00 06 F0 55 AA 52 08 00
			];
			/* <mipi_address  update_index  update_length> */
			mi,mdss-dsi-switch-page-command-update = <0xF0 0 5>;
			mi,mdss-dsi-switch-page-command-state = "dsi_lp_mode";

			mi,mdss-dsi-flat-mode-read-pre-command = [
				39 00 00 00 00 00 06 F0 55 AA 52 08 00
				39 00 00 00 00 00 02 6F 3F
			];
			mi,mdss-dsi-flat-mode-read-pre-command-state = "dsi_lp_mode";

			mi,mdss-dsi-flat-mode-off-read-pre-command = [
				39 00 00 00 00 00 06 F0 55 AA 52 08 00
				39 00 00 00 00 00 02 6F 48
			];
			mi,mdss-dsi-flat-mode-off-read-pre-command-state = "dsi_lp_mode";

			mi,mdss-dsi-flat-mode-on-command = [
				/* 120 Hz gir cmd_1,need sync te*/
				39 00 00 00 00 00 02 2F 02
				39 00 00 40 00 00 06 F0 55 AA 52 08 00
				39 00 00 40 00 00 02 6F 09
				39 00 00 40 00 00 02 C0 60
				39 00 00 40 00 00 06 F0 55 AA 52 08 02
				39 00 00 40 00 00 02 CC 30
				39 00 00 40 00 00 02 CE 01
				39 00 00 40 00 00 06 F0 55 AA 52 08 08
				39 00 00 40 00 00 02 6F 07
				39 00 00 20 14 00 05 B9 00 00 00 00
			];
			/* <mipi_address  update_index  update_length> */
			mi,mdss-dsi-flat-mode-on-command-update = <0xB9 9 4>;

			mi,mdss-dsi-flat-mode-on-sec-command = [
				/* 120 Hz gir cmd_2*/
				39 00 00 00 00 00 06 F0 55 AA 52 08 02
				39 00 00 00 00 00 02 CC 00
			];
			mi,mdss-dsi-flat-mode-on-command-state = "dsi_hs_mode";
			mi,mdss-dsi-flat-mode-on-sec-command-state = "dsi_lp_mode";

			mi,mdss-dsi-flat-mode-off-command = [
				/* 120 Hz gir cmd_1,need sync te*/
				39 00 00 00 00 00 02 2F 02
				39 00 00 40 00 00 06 F0 55 AA 52 08 00
				39 00 00 40 00 00 02 6F 09
				39 00 00 40 00 00 02 C0 20
				39 00 00 40 00 00 06 F0 55 AA 52 08 02
				39 00 00 40 00 00 02 CC 30
				39 00 00 40 00 00 02 CE 01
				39 00 00 40 00 00 06 F0 55 AA 52 08 08
				39 00 00 40 00 00 02 6F 07
				39 00 00 20 14 00 05 B9 00 00 00 18
			];
			/* <mipi_address  update_index  update_length> */
			mi,mdss-dsi-flat-mode-off-command-update = <0xB9 9 4>;
			mi,mdss-dsi-flat-mode-off-sec-command = [
				/* 120 Hz gir cmd_2*/
				39 00 00 00 00 00 06 F0 55 AA 52 08 02
				39 00 00 00 00 00 02 CC 00
			];
			mi,mdss-dsi-flat-mode-off-command-state = "dsi_hs_mode";
			mi,mdss-dsi-flat-mode-off-sec-command-state = "dsi_lp_mode";

			mi,mdss-dsi-doze-hbm-command = [
				39 00 00 00 00 00 02 2F 01
				39 00 00 40 00 00 02 26 01
				39 00 00 40 00 00 06 F0 55 AA 52 08 00
				39 00 00 40 00 00 02 B2 08
				39 00 00 40 00 00 05 51 00 F5 0F FE
				39 00 00 00 00 00 02 39 00
			];
			mi,mdss-dsi-doze-hbm-command-state = "dsi_lp_mode";

			mi,mdss-dsi-doze-lbm-command = [
				39 00 00 00 00 00 02 2F 01
				39 00 00 40 00 00 02 26 01
				39 00 00 40 00 00 06 F0 55 AA 52 08 00
				39 00 00 40 00 00 02 B2 08
				39 00 00 40 00 00 05 51 00 14 01 55
				39 00 00 00 00 00 02 39 00
			];
			mi,mdss-dsi-doze-lbm-command-state = "dsi_lp_mode";

			mi,mdss-dsi-doze-hbm-nolp-command = [
				39 00 00 00 00 00 06 F0 55 AA 52 08 00
				39 00 00 40 00 00 02 B2 18
				39 00 00 40 00 00 05 51 00 F5 0F FE
				39 00 00 00 00 00 02 38 00
				39 00 00 00 00 00 02 2F 02
			];
			mi,mdss-dsi-doze-hbm-nolp-command-state = "dsi_lp_mode";

			mi,mdss-dsi-doze-lbm-nolp-command = [
				39 00 00 00 00 00 06 F0 55 AA 52 08 00
				39 00 00 40 00 00 02 B2 18
				39 00 00 40 00 00 05 51 00 14 01 55
				39 00 00 00 00 00 02 38 00
				39 00 00 00 00 00 02 2F 02
			];
			mi,mdss-dsi-doze-lbm-nolp-command-state = "dsi_lp_mode";

			mi,mdss-dsi-local-hbm-normal-white-1000nit-command = [
				39 00 00 00 00 00 06 F0 55 AA 52 08 00
				39 00 00 40 00 00 02 6F 29
				39 00 00 40 00 00 02 D9 00
				39 00 00 40 00 00 02 6F 01
				39 00 00 40 00 00 02 D9 80
				39 00 00 40 00 00 02 6F 07
				39 00 00 40 00 00 03 B2 07 FF
				39 00 00 40 00 00 02 6F 17
				39 00 00 40 00 00 03 B2 07 FF
				39 00 00 40 00 00 02 6F 1F
				39 00 00 40 00 00 03 B2 00 50
				39 00 00 40 00 00 06 F0 55 AA 52 08 02
				39 00 00 40 00 00 02 6F 08
				39 00 00 40 00 00 07 D0 0B 07 09 7B 0C 1D
				39 00 00 40 00 00 06 F0 55 AA 52 08 07
				39 00 00 40 00 00 02 C0 05
				39 00 00 40 00 00 02 53 20
				39 00 00 40 00 00 05 88 02 1C 08 73
				39 00 00 40 00 00 03 51 07 FF
				39 00 00 40 00 00 03 87 04 4E
				39 00 00 40 00 00 02 6F 02
				39 00 00 00 30 00 02 87 05
			];
			mi,mdss-dsi-local-hbm-normal-white-1000nit-command-update = <0x87 19 2>, <0xD0 13 6>;
			mi,mdss-dsi-local-hbm-normal-white-1000nit-command-state = "dsi_hs_mode";

			mi,mdss-dsi-local-hbm-hlpm-white-1000nit-command = [
				/* AOD off */
				39 00 00 00 00 00 06 F0 55 AA 52 08 00
				39 00 00 40 00 00 02 B2 18
				39 00 00 40 00 00 02 38 00
				39 00 00 00 00 00 02 2F 02
				/* Local HBM setting*/
				39 00 00 40 00 00 06 F0 55 AA 52 08 00
				39 00 00 40 00 00 02 6F 29
				39 00 00 40 00 00 02 D9 00
				39 00 00 40 00 00 02 6F 01
				39 00 00 40 00 00 02 D9 80
				39 00 00 40 00 00 02 6F 07
				39 00 00 40 00 00 03 B2 07 FF
				39 00 00 40 00 00 02 6F 17
				39 00 00 40 00 00 03 B2 07 FF
				39 00 00 40 00 00 02 6F 1F
				39 00 00 40 00 00 03 B2 00 50
				39 00 00 40 00 00 06 F0 55 AA 52 08 02
				39 00 00 40 00 00 02 6F 08
				39 00 00 40 00 00 07 D0 0B 07 09 7B 0C 1D
				39 00 00 40 00 00 06 F0 55 AA 52 08 07
				39 00 00 40 00 00 02 C0 05
				39 00 00 40 00 00 02 53 20
				39 00 00 40 00 00 05 88 02 1C 08 73
				39 00 00 40 00 00 03 51 07 FF
				39 00 00 40 00 00 03 87 04 4E
				39 00 00 40 00 00 02 6F 02
				39 00 00 00 30 00 02 87 05
			];
			mi,mdss-dsi-local-hbm-hlpm-white-1000nit-command-update = <0x87 23 2>, <0xD0 17 6>;
			mi,mdss-dsi-local-hbm-hlpm-white-1000nit-command-state = "dsi_hs_mode";

			mi,mdss-dsi-local-hbm-normal-white-110nit-command = [
				39 00 00 00 00 00 06 F0 55 AA 52 08 00
				39 00 00 40 00 00 02 6F 29
				39 00 00 40 00 00 02 D9 00
				39 00 00 40 00 00 02 6F 01
				39 00 00 40 00 00 02 D9 80
				39 00 00 40 00 00 02 6F 07
				39 00 00 40 00 00 03 B2 07 FF
				39 00 00 40 00 00 02 6F 17
				39 00 00 40 00 00 03 B2 07 FF
				39 00 00 40 00 00 02 6F 1F
				39 00 00 40 00 00 03 B2 00 50
				39 00 00 40 00 00 06 F0 55 AA 52 08 02
				39 00 00 40 00 00 02 6F 08
				39 00 00 40 00 00 07 D0 0B 07 09 7B 0C 1D
				39 00 00 40 00 00 06 F0 55 AA 52 08 07
				39 00 00 40 00 00 02 C0 05
				39 00 00 40 00 00 02 53 20
				39 00 00 40 00 00 05 88 02 1C 08 73
				39 00 00 40 00 00 03 51 07 FF
				39 00 00 40 00 00 03 87 04 4E
				39 00 00 40 00 00 02 6F 02
				39 00 00 00 30 00 02 87 05
			];
			mi,mdss-dsi-local-hbm-normal-white-110nit-command-update = <0x87 19 2>, <0xD0 13 6>;
			mi,mdss-dsi-local-hbm-normal-white-110nit-command-state = "dsi_hs_mode";

			mi,mdss-dsi-local-hbm-hlpm-white-110nit-command = [
				/* AOD off */
				39 00 00 00 00 00 06 F0 55 AA 52 08 00
				39 00 00 40 00 00 02 B2 18
				39 00 00 40 00 00 02 38 00
				39 00 00 00 00 00 02 2F 02
				/* Local HBM setting*/
				39 00 00 40 00 00 06 F0 55 AA 52 08 00
				39 00 00 40 00 00 02 6F 29
				39 00 00 40 00 00 02 D9 00
				39 00 00 40 00 00 02 6F 01
				39 00 00 40 00 00 02 D9 80
				39 00 00 40 00 00 02 6F 07
				39 00 00 40 00 00 03 B2 07 FF
				39 00 00 40 00 00 02 6F 17
				39 00 00 40 00 00 03 B2 07 FF
				39 00 00 40 00 00 02 6F 1F
				39 00 00 40 00 00 03 B2 00 50
				39 00 00 40 00 00 06 F0 55 AA 52 08 02
				39 00 00 40 00 00 02 6F 08
				39 00 00 40 00 00 07 D0 0B 07 09 7B 0C 1D
				39 00 00 40 00 00 06 F0 55 AA 52 08 07
				39 00 00 40 00 00 02 C0 05
				39 00 00 40 00 00 02 53 20
				39 00 00 40 00 00 05 88 02 1C 08 73
				39 00 00 40 00 00 03 51 07 FF
				39 00 00 40 00 00 03 87 04 4E
				39 00 00 40 00 00 02 6F 02
				39 00 00 00 30 00 02 87 05
			];
			mi,mdss-dsi-local-hbm-hlpm-white-110nit-command-update = <0x87 23 2>, <0xD0 17 6>;
			mi,mdss-dsi-local-hbm-hlpm-white-110nit-command-state = "dsi_hs_mode";

			mi,mdss-dsi-local-hbm-normal-green-500nit-command = [
				39 00 00 00 00 00 06 F0 55 AA 52 08 00
				39 00 00 40 00 00 02 6F 29
				39 00 00 40 00 00 02 D9 00
				39 00 00 40 00 00 02 6F 01
				39 00 00 40 00 00 02 D9 80
				39 00 00 40 00 00 02 6F 07
				39 00 00 40 00 00 03 B2 07 FF
				39 00 00 40 00 00 02 6F 17
				39 00 00 40 00 00 03 B2 07 FF
				39 00 00 40 00 00 02 6F 1F
				39 00 00 40 00 00 03 B2 00 50
				39 00 00 40 00 00 06 F0 55 AA 52 08 02
				39 00 00 40 00 00 02 6F 08
				39 00 00 40 00 00 07 D0 00 00 09 40 00 00
				39 00 00 40 00 00 06 F0 55 AA 52 08 07
				39 00 00 40 00 00 02 C0 05
				39 00 00 40 00 00 02 53 20
				39 00 00 40 00 00 05 88 02 1C 08 73
				39 00 00 40 00 00 03 51 07 FF
				39 00 00 40 00 00 03 87 04 4E
				39 00 00 40 00 00 02 6F 02
				39 00 00 00 30 00 02 87 05
			];
			mi,mdss-dsi-local-hbm-normal-green-500nit-command-update = <0x87 19 2>, <0xD0 13 6>;
			mi,mdss-dsi-local-hbm-normal-green-500nit-command-state = "dsi_hs_mode";

			mi,mdss-dsi-local-hbm-off-to-normal-command = [
				39 00 00 00 00 00 02 53 20
				39 00 00 40 00 00 03 51 00 00
				39 00 00 40 00 00 02 6F 02
				39 00 00 00 00 00 02 87 04
			];
			mi,mdss-dsi-local-hbm-off-to-normal-command-update = <0x51 1 2>;
			mi,mdss-dsi-local-hbm-off-to-normal-command-state = "dsi_hs_mode";

			mi,mdss-dsi-local-hbm-off-to-hbm-command = [
				39 00 00 00 00 00 02 53 20
				39 00 00 40 00 00 03 51 00 00
				39 00 00 40 00 00 02 6F 02
				39 00 00 00 00 00 02 87 04
			];
			mi,mdss-dsi-local-hbm-off-to-hbm-command-update = <0x51 1 2>;
			mi,mdss-dsi-local-hbm-off-to-hbm-command-state = "dsi_hs_mode";

			mi,mdss-dsi-local-hbm-off-to-hlpm-command = [
				/* local hbm off */
				39 00 00 00 00 00 02 53 20
				39 00 00 40 00 00 03 51 00 00
				39 00 00 40 00 00 02 6F 02
				39 00 00 40 00 00 02 87 04
				/* aod hbm */
				39 00 00 40 00 00 02 2F 01
				39 00 00 40 00 00 02 26 01
				39 00 00 40 00 00 06 F0 55 AA 52 08 00
				39 00 00 40 00 00 02 B2 08
				39 00 00 40 00 00 05 51 00 F5 0F FF
				39 00 00 00 00 00 02 39 00
			];
			mi,mdss-dsi-local-hbm-off-to-hlpm-command-state = "dsi_hs_mode";

			mi,mdss-dsi-local-hbm-off-to-llpm-command = [
				/* local hbm off */
				39 00 00 00 00 00 02 53 20
				39 00 00 40 00 00 03 51 00 00
				39 00 00 40 00 00 02 6F 02
				39 00 00 40 00 00 02 87 04
				/* aod lbm */
				39 00 00 40 00 00 02 2F 01
				39 00 00 40 00 00 02 26 01
				39 00 00 40 00 00 06 F0 55 AA 52 08 00
				39 00 00 40 00 00 02 B2 08
				39 00 00 40 00 00 05 51 00 14 01 55
				39 00 00 00 00 00 02 39 00
			];
			mi,mdss-dsi-local-hbm-off-to-llpm-command-state = "dsi_hs_mode";

			mi,mdss-dsi-pre-doze-to-off-command = [
				39 01 00 00 00 00 06 F0 55 AA 52 08 01
				39 01 00 00 00 00 02 CE 0C];
			mi,mdss-dsi-pre-doze-to-off-command-state = "dsi_hs_mode";
		};

		/* 90Hz */
		timing@2{
			mi,mdss-dsc-panel-id = <0x004C3953 0x00420200>;
			/*<flat on gamma, flat off gamma>*/
			mi,mdss-flat-status-control-gamma-cfg = <0x60 0x20>;
			mi,mdss-dsi-dimmingon-command = [39 00 00 00 00 00 02 53 28];
			mi,mdss-dsi-dimmingon-command-state = "dsi_hs_mode";
			mi,mdss-dsi-dimmingoff-command = [39 00 00 00 00 00 02 53 20];
			mi,mdss-dsi-dimmingoff-command-state = "dsi_hs_mode";

			mi,mdss-dsi-hbm-on-command = [39 00 00 00 00 00 05 51 0F FF 00 00];
			mi,mdss-dsi-hbm-on-command-state = "dsi_lp_mode";
			mi,mdss-dsi-hbm-off-command = [39 00 00 00 00 00 05 51 07 FF 00 00];
			mi,mdss-dsi-hbm-off-command-state = "dsi_lp_mode";

			mi,mdss-dsi-switch-page-command = [
			/* switch page, last byte is page config */
				39 00 00 00 00 00 06 F0 55 AA 52 08 00
			];
			/* <mipi_address  update_index  update_length> */
			mi,mdss-dsi-switch-page-command-update = <0xF0 0 5>;
			mi,mdss-dsi-switch-page-command-state = "dsi_lp_mode";

			mi,mdss-dsi-flat-mode-read-pre-command = [
				39 00 00 00 00 00 06 F0 55 AA 52 08 00
				39 00 00 00 00 00 02 6F 3F
			];
			mi,mdss-dsi-flat-mode-read-pre-command-state = "dsi_lp_mode";

			mi,mdss-dsi-flat-mode-off-read-pre-command = [
				39 00 00 00 00 00 06 F0 55 AA 52 08 00
				39 00 00 00 00 00 02 6F 48
			];
			mi,mdss-dsi-flat-mode-off-read-pre-command-state = "dsi_lp_mode";

			mi,mdss-dsi-flat-mode-on-command = [
				/* 90 Hz gir cmd_1,need sync te*/
				39 00 00 00 00 00 02 2F 03
				39 00 00 40 00 00 06 F0 55 AA 52 08 00
				39 00 00 40 00 00 02 6F 0A
				39 00 00 40 00 00 02 C0 60
				39 00 00 40 00 00 06 F0 55 AA 52 08 02
				39 00 00 40 00 00 02 CC 30
				39 00 00 40 00 00 02 CE 01
				39 00 00 40 00 00 06 F0 55 AA 52 08 08
				39 00 00 40 00 00 02 6F 07
				39 00 00 20 14 00 05 B9 00 00 00 00
			];
			/* <mipi_address  update_index  update_length> */
			mi,mdss-dsi-flat-mode-on-command-update = <0xB9 9 4>;

			mi,mdss-dsi-flat-mode-on-sec-command = [
				/* 90 Hz gir cmd_2*/
				39 00 00 00 00 00 06 F0 55 AA 52 08 02
				39 00 00 00 00 00 02 CC 00
			];
			mi,mdss-dsi-flat-mode-on-command-state = "dsi_lp_mode";
			mi,mdss-dsi-flat-mode-on-sec-command-state = "dsi_lp_mode";

			mi,mdss-dsi-flat-mode-off-command = [
				/* 90 Hz gir cmd_1,need sync te*/
				39 00 00 00 00 00 02 2F 03
				39 00 00 40 00 00 06 F0 55 AA 52 08 00
				39 00 00 40 00 00 02 6F 0A
				39 00 00 40 00 00 02 C0 20
				39 00 00 40 00 00 06 F0 55 AA 52 08 02
				39 00 00 40 00 00 02 CC 30
				39 00 00 40 00 00 02 CE 01
				39 00 00 40 00 00 06 F0 55 AA 52 08 08
				39 00 00 40 00 00 02 6F 07
				39 00 00 20 14 00 05 B9 00 00 00 18
			];
			/* <mipi_address  update_index  update_length> */
			mi,mdss-dsi-flat-mode-off-command-update = <0xB9 9 4>;
			mi,mdss-dsi-flat-mode-off-sec-command = [
				/* 90 Hz gir cmd_2*/
				39 00 00 00 00 00 06 F0 55 AA 52 08 02
				39 00 00 00 00 00 02 CC 00
			];
			mi,mdss-dsi-flat-mode-off-command-state = "dsi_lp_mode";
			mi,mdss-dsi-flat-mode-off-sec-command-state = "dsi_lp_mode";

			mi,mdss-dsi-doze-hbm-command = [
				39 00 00 00 00 00 02 2F 01
				39 00 00 40 00 00 02 26 01
				39 00 00 40 00 00 06 F0 55 AA 52 08 00
				39 00 00 40 00 00 02 B2 08
				39 00 00 40 00 00 05 51 00 F5 0F FE
				39 00 00 00 00 00 02 39 00
			];
			mi,mdss-dsi-doze-hbm-command-state = "dsi_lp_mode";

			mi,mdss-dsi-doze-lbm-command = [
				39 00 00 00 00 00 02 2F 01
				39 00 00 40 00 00 02 26 01
				39 00 00 40 00 00 06 F0 55 AA 52 08 00
				39 00 00 40 00 00 02 B2 08
				39 00 00 40 00 00 05 51 00 14 01 55
				39 00 00 00 00 00 02 39 00
			];
			mi,mdss-dsi-doze-lbm-command-state = "dsi_lp_mode";

			mi,mdss-dsi-doze-hbm-nolp-command = [
				39 00 00 00 00 00 06 F0 55 AA 52 08 00
				39 00 00 40 00 00 02 B2 18
				39 00 00 40 00 00 05 51 00 F5 0F FE
				39 00 00 00 00 00 02 38 00
			];
			mi,mdss-dsi-doze-hbm-nolp-command-state = "dsi_lp_mode";

			mi,mdss-dsi-doze-lbm-nolp-command = [
				39 00 00 00 00 00 06 F0 55 AA 52 08 00
				39 00 00 40 00 00 02 B2 18
				39 00 00 40 00 00 05 51 00 14 01 55
				39 00 00 00 00 00 02 38 00
			];
			mi,mdss-dsi-doze-lbm-nolp-command-state = "dsi_lp_mode";

			mi,mdss-dsi-local-hbm-normal-white-1000nit-command = [
				39 00 00 00 00 00 06 F0 55 AA 52 08 00
				39 00 00 40 00 00 02 6F 29
				39 00 00 40 00 00 02 D9 00
				39 00 00 40 00 00 02 6F 01
				39 00 00 40 00 00 02 D9 80
				39 00 00 40 00 00 02 6F 07
				39 00 00 40 00 00 03 B2 07 FF
				39 00 00 40 00 00 02 6F 17
				39 00 00 40 00 00 03 B2 07 FF
				39 00 00 40 00 00 02 6F 1F
				39 00 00 40 00 00 03 B2 00 50
				39 00 00 40 00 00 06 F0 55 AA 52 08 02
				39 00 00 40 00 00 02 6F 08
				39 00 00 40 00 00 07 D0 0B 07 09 7B 0C 1D
				39 00 00 40 00 00 06 F0 55 AA 52 08 07
				39 00 00 40 00 00 02 C0 05
				39 00 00 40 00 00 02 53 20
				39 00 00 40 00 00 05 88 02 1C 08 73
				39 00 00 40 00 00 03 51 07 FF
				39 00 00 40 00 00 03 87 04 4E
				39 00 00 40 00 00 02 6F 02
				39 00 00 00 30 00 02 87 05
			];
			mi,mdss-dsi-local-hbm-normal-white-1000nit-command-update = <0x87 19 2>, <0xD0 13 6>;
			mi,mdss-dsi-local-hbm-normal-white-1000nit-command-state = "dsi_hs_mode";

			mi,mdss-dsi-local-hbm-hlpm-white-1000nit-command = [
				/* AOD off */
				39 00 00 00 00 00 06 F0 55 AA 52 08 00
				39 00 00 40 00 00 02 B2 18
				39 00 00 40 00 00 02 38 00
				/* Local HBM setting*/
				39 00 00 40 00 00 06 F0 55 AA 52 08 00
				39 00 00 40 00 00 02 6F 29
				39 00 00 40 00 00 02 D9 00
				39 00 00 40 00 00 02 6F 01
				39 00 00 40 00 00 02 D9 80
				39 00 00 40 00 00 02 6F 07
				39 00 00 40 00 00 03 B2 07 FF
				39 00 00 40 00 00 02 6F 17
				39 00 00 40 00 00 03 B2 07 FF
				39 00 00 40 00 00 02 6F 1F
				39 00 00 40 00 00 03 B2 00 50
				39 00 00 40 00 00 06 F0 55 AA 52 08 02
				39 00 00 40 00 00 02 6F 08
				39 00 00 40 00 00 07 D0 0B 07 09 7B 0C 1D
				39 00 00 40 00 00 06 F0 55 AA 52 08 07
				39 00 00 40 00 00 02 C0 05
				39 00 00 40 00 00 02 53 20
				39 00 00 40 00 00 05 88 02 1C 08 73
				39 00 00 40 00 00 03 51 07 FF
				39 00 00 40 00 00 03 87 04 4E
				39 00 00 40 00 00 02 6F 02
				39 00 00 00 30 00 02 87 05
			];
			mi,mdss-dsi-local-hbm-hlpm-white-1000nit-command-update = <0x87 22 2>, <0xD0 16 6>;
			mi,mdss-dsi-local-hbm-hlpm-white-1000nit-command-state = "dsi_hs_mode";

			mi,mdss-dsi-local-hbm-normal-white-110nit-command = [
				39 00 00 00 00 00 06 F0 55 AA 52 08 00
				39 00 00 40 00 00 02 6F 29
				39 00 00 40 00 00 02 D9 00
				39 00 00 40 00 00 02 6F 01
				39 00 00 40 00 00 02 D9 80
				39 00 00 40 00 00 02 6F 07
				39 00 00 40 00 00 03 B2 07 FF
				39 00 00 40 00 00 02 6F 17
				39 00 00 40 00 00 03 B2 07 FF
				39 00 00 40 00 00 02 6F 1F
				39 00 00 40 00 00 03 B2 00 50
				39 00 00 40 00 00 06 F0 55 AA 52 08 02
				39 00 00 40 00 00 02 6F 08
				39 00 00 40 00 00 07 D0 0B 07 09 7B 0C 1D
				39 00 00 40 00 00 06 F0 55 AA 52 08 07
				39 00 00 40 00 00 02 C0 05
				39 00 00 40 00 00 02 53 20
				39 00 00 40 00 00 05 88 02 1C 08 73
				39 00 00 40 00 00 03 51 07 FF
				39 00 00 40 00 00 03 87 04 4E
				39 00 00 40 00 00 02 6F 02
				39 00 00 00 30 00 02 87 05
			];
			mi,mdss-dsi-local-hbm-normal-white-110nit-command-update = <0x87 19 2>, <0xD0 13 6>;
			mi,mdss-dsi-local-hbm-normal-white-110nit-command-state = "dsi_hs_mode";

			mi,mdss-dsi-local-hbm-hlpm-white-110nit-command = [
				/* AOD off */
				39 00 00 00 00 00 06 F0 55 AA 52 08 00
				39 00 00 40 00 00 02 B2 18
				39 00 00 40 00 00 02 38 00
				/* Local HBM setting*/
				39 00 00 40 00 00 06 F0 55 AA 52 08 00
				39 00 00 40 00 00 02 6F 29
				39 00 00 40 00 00 02 D9 00
				39 00 00 40 00 00 02 6F 01
				39 00 00 40 00 00 02 D9 80
				39 00 00 40 00 00 02 6F 07
				39 00 00 40 00 00 03 B2 07 FF
				39 00 00 40 00 00 02 6F 17
				39 00 00 40 00 00 03 B2 07 FF
				39 00 00 40 00 00 02 6F 1F
				39 00 00 40 00 00 03 B2 00 50
				39 00 00 40 00 00 06 F0 55 AA 52 08 02
				39 00 00 40 00 00 02 6F 08
				39 00 00 40 00 00 07 D0 0B 07 09 7B 0C 1D
				39 00 00 40 00 00 06 F0 55 AA 52 08 07
				39 00 00 40 00 00 02 C0 05
				39 00 00 40 00 00 02 53 20
				39 00 00 40 00 00 05 88 02 1C 08 73
				39 00 00 40 00 00 03 51 07 FF
				39 00 00 40 00 00 03 87 04 4E
				39 00 00 40 00 00 02 6F 02
				39 00 00 00 30 00 02 87 05
			];
			mi,mdss-dsi-local-hbm-hlpm-white-110nit-command-update = <0x87 22 2>, <0xD0 16 6>;
			mi,mdss-dsi-local-hbm-hlpm-white-110nit-command-state = "dsi_hs_mode";

			mi,mdss-dsi-local-hbm-normal-green-500nit-command = [
				39 00 00 00 00 00 06 F0 55 AA 52 08 00
				39 00 00 40 00 00 02 6F 29
				39 00 00 40 00 00 02 D9 00
				39 00 00 40 00 00 02 6F 01
				39 00 00 40 00 00 02 D9 80
				39 00 00 40 00 00 02 6F 07
				39 00 00 40 00 00 03 B2 07 FF
				39 00 00 40 00 00 02 6F 17
				39 00 00 40 00 00 03 B2 07 FF
				39 00 00 40 00 00 02 6F 1F
				39 00 00 40 00 00 03 B2 00 50
				39 00 00 40 00 00 06 F0 55 AA 52 08 02
				39 00 00 40 00 00 02 6F 08
				39 00 00 40 00 00 07 D0 00 00 09 40 00 00
				39 00 00 40 00 00 06 F0 55 AA 52 08 07
				39 00 00 40 00 00 02 C0 05
				39 00 00 40 00 00 02 53 20
				39 00 00 40 00 00 05 88 02 1C 08 73
				39 00 00 40 00 00 03 51 07 FF
				39 00 00 40 00 00 03 87 04 4E
				39 00 00 40 00 00 02 6F 02
				39 00 00 00 30 00 02 87 05
			];
			mi,mdss-dsi-local-hbm-normal-green-500nit-command-update = <0x87 19 2>, <0xD0 13 6>;
			mi,mdss-dsi-local-hbm-normal-green-500nit-command-state = "dsi_hs_mode";

			mi,mdss-dsi-local-hbm-off-to-normal-command = [
				39 00 00 00 00 00 02 53 20
				39 00 00 40 00 00 03 51 00 00
				39 00 00 40 00 00 02 6F 02
				39 00 00 00 00 00 02 87 04
			];
			mi,mdss-dsi-local-hbm-off-to-normal-command-update = <0x51 1 2>;
			mi,mdss-dsi-local-hbm-off-to-normal-command-state = "dsi_hs_mode";

			mi,mdss-dsi-local-hbm-off-to-hbm-command = [
				39 00 00 00 00 00 02 53 20
				39 00 00 40 00 00 03 51 00 00
				39 00 00 40 00 00 02 6F 02
				39 00 00 00 00 00 02 87 04
			];
			mi,mdss-dsi-local-hbm-off-to-hbm-command-update = <0x51 1 2>;
			mi,mdss-dsi-local-hbm-off-to-hbm-command-state = "dsi_hs_mode";

			mi,mdss-dsi-local-hbm-off-to-hlpm-command = [
				/* local hbm off */
				39 00 00 00 00 00 02 53 20
				39 00 00 40 00 00 03 51 00 00
				39 00 00 40 00 00 02 6F 02
				39 00 00 40 00 00 02 87 04
				/* aod hbm */
				39 00 00 40 00 00 02 2F 01
				39 00 00 40 00 00 02 26 01
				39 00 00 40 00 00 06 F0 55 AA 52 08 00
				39 00 00 40 00 00 02 B2 08
				39 00 00 40 00 00 05 51 00 F5 0F FF
				39 00 00 00 00 00 02 39 00
			];
			mi,mdss-dsi-local-hbm-off-to-hlpm-command-state = "dsi_hs_mode";

			mi,mdss-dsi-local-hbm-off-to-llpm-command = [
				/* local hbm off */
				39 00 00 00 00 00 02 53 20
				39 00 00 40 00 00 03 51 00 00
				39 00 00 40 00 00 02 6F 02
				39 00 00 40 00 00 02 87 04
				/* aod lbm */
				39 00 00 40 00 00 02 2F 01
				39 00 00 40 00 00 02 26 01
				39 00 00 40 00 00 06 F0 55 AA 52 08 00
				39 00 00 40 00 00 02 B2 08
				39 00 00 40 00 00 05 51 00 14 01 55
				39 00 00 00 00 00 02 39 00
			];
			mi,mdss-dsi-local-hbm-off-to-llpm-command-state = "dsi_hs_mode";

			mi,mdss-dsi-pre-doze-to-off-command = [
				39 01 00 00 00 00 06 F0 55 AA 52 08 01
				39 01 00 00 00 00 02 CE 0C];
			mi,mdss-dsi-pre-doze-to-off-command-state = "dsi_hs_mode";
		};
	};
};
